# RL6845_IP_SVD register map
Vendor: Realtek
Registers are 32-bit, read-write, reset 0x0 unless marked. A register's access mark holds for its fields unless they carry their own. Offsets are from the block's base; [hi:lo] are bit positions; {n}, {i} and the like mark numbered series.

## Cap-Touch
Base 0x41012000
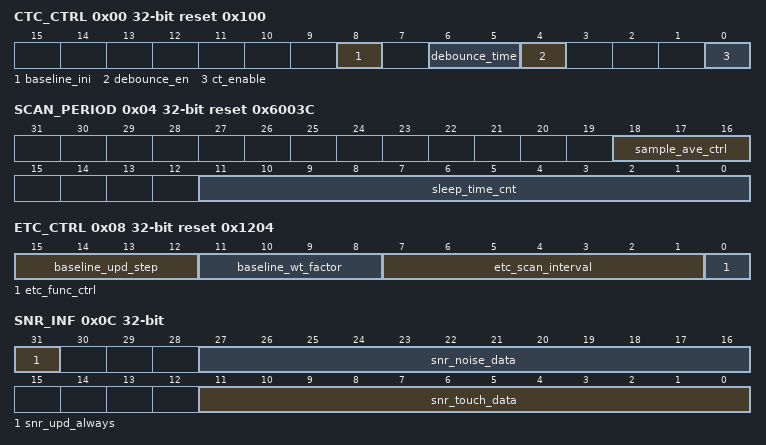
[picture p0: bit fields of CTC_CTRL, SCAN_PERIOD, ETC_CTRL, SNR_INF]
0x00 CTC_CTRL reset 0x100 — Cap-Touch Control Register
  [8] baseline_ini — 1: Baseline initial function enable, HW will clear this bit to "0" after baseline initial
  [6:5] debounce_time — 2'b00: 2 times 2'b01: 3 times 2'b10: 4 times 2'b11: 5 times
  [4] debounce_en — 0: Disable 1: Enable
  [0] ct_enable — 0: CTC disable 1: CTC enable
0x04 SCAN_PERIOD reset 0x6003C — Scan Parameters Register
  [18:16] sample_ave_ctrl — ADC sampled number for average function average number=2^(sample_ave_ctrl+2)
  [11:0] sleep_time_cnt — Code: 0~4095 (0~0xFFF), unit is 1.024kHz cycle (1/32 32.768kHz). When this register is set to 0 , HW will scan continuously and have no sleep time. Recommend value: 60~480ms
0x08 ETC_CTRL reset 0x1204 — Environment Tracking Control Register
  [15:12] baseline_upd_step — Baseline update step for all channels
  [11:8] baseline_wt_factor — Baseline update weight factor (ETC_factor_th) for all channels ETC_factor_th=2^baseline_wt_factor
  [7:1] etc_scan_interval — ETC update interval between scan period (sleep time) for all channels Interval=(etc_scan_interval+1)*scan_period
  [0] etc_func_ctrl — Environmental cap tracking calibration function 0: Disable 1: Enable
0x0C SNR_INF — Signal Noise Ratio Register
  [31] snr_upd_always — 1: Update SNR info no matter touch or not (used only in debug function)
  [27:16] snr_noise_data — Noise peak to peak signal raw data for SNR monitor
  [11:0] snr_touch_data — Raw data of touch (signal-baseline) for SNR monitor
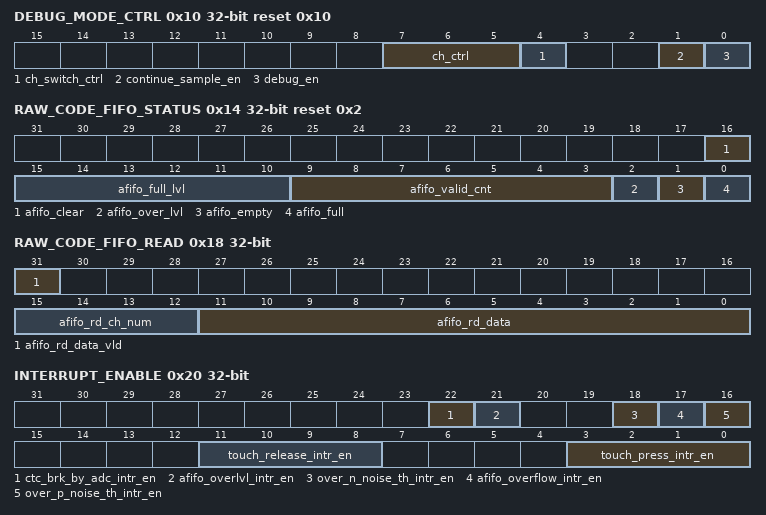
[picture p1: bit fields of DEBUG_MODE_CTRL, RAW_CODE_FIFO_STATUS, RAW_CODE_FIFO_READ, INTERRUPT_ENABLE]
0x10 DEBUG_MODE_CTRL reset 0x10 — Debug and Channel Swith Mode Register
  [7:5] ch_ctrl — Scan channel control 000: channel 0 001: channel 1 010: channel 2 011: channel 3
  [4] ch_switch_ctrl — Scan channel switch control 0: Auto switch function disable (manual switch by ch_ctrl) 1: Auto switch to next channel (channel 0 -> channel 3 -> channel 0)
  [1] continue_sample_en — Continue sample one channel mode enable, only take effect in debug mode 0: Disable 1: Enable
  [0] debug_en — Debug mode enable 0: Disable 1: Enable
0x14 RAW_CODE_FIFO_STATUS access per field reset 0x2 — FIFO Status Register
  [16] afifo_clear wo — Clear the FIFO data
  [15:10] afifo_full_lvl rw — User defines the full level for a FIFO, the valid value is from 0 to 63
  [9:3] afifo_valid_cnt ro — Raw code FIFO valid count (push unit number which can be read)
  [2] afifo_over_lvl ro — 0: Raw code FIFO not over level 1: Raw code FIFO over level
  [1] afifo_empty ro — 0: Raw code FIFO not empty 1: Raw code FIFO empty
  [0] afifo_full ro — 0: Raw code FIFO not oveflow (not full) 1: Raw code FIFO overflow (full)
0x18 RAW_CODE_FIFO_READ ro — FIFO Read Register
  [31] afifo_rd_data_vld — Read data from raw code FIFO valid
  [15:12] afifo_rd_ch_num — Read data from raw code FIFO [15:12] : channel number
  [11:0] afifo_rd_data — Read data from raw code FIFO [11:0] : data
0x20 INTERRUPT_ENABLE
  [22] ctc_brk_by_adc_intr_en — Cap-Touch breaked by ADC enable
  [21] afifo_overlvl_intr_en — Raw code FIFO over level enable
  [18] over_n_noise_th_intr_en — Negative noise threshold overflow enable
  [17] afifo_overflow_intr_en — Raw code FIFO overflow enable
  [16] over_p_noise_th_intr_en — Positive noise threshold overflow enable
  [11:8] touch_release_intr_en — Channelx single touch release enable, x is 0~3
  [3:0] touch_press_intr_en — Channelx single touch press enable, x is 0~3
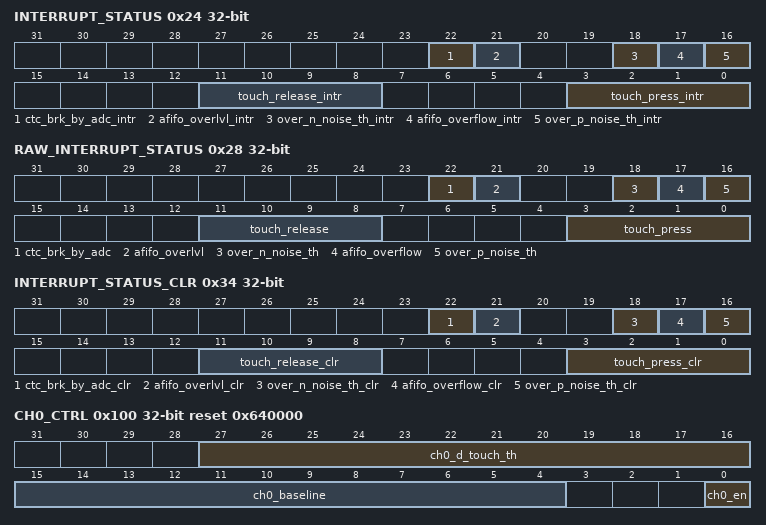
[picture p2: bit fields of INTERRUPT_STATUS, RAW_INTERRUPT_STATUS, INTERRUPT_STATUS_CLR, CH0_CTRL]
0x24 INTERRUPT_STATUS ro
  [22] ctc_brk_by_adc_intr — Cap-Touch breaked by adc interrupt
  [21] afifo_overlvl_intr — Raw code FIFO over level interrupt
  [18] over_n_noise_th_intr — Negative noise threshold overflow interrupt
  [17] afifo_overflow_intr — Raw code FIFO overflow interrupt
  [16] over_p_noise_th_intr — Positive noise threshold overflow interrupt
  [11:8] touch_release_intr — Channelx single touch release interrupt, x is 0~3
  [3:0] touch_press_intr — Channelx single touch press interrupt, x is 0~3
0x28 RAW_INTERRUPT_STATUS ro
  [22] ctc_brk_by_adc — Cap-Touch breaked by ADC raw interrupt
  [21] afifo_overlvl — Raw code FIFO over level raw interrupt
  [18] over_n_noise_th — Negative noise threshold overflow raw interrupt
  [17] afifo_overflow — Raw code FIFO overflow raw interrupt
  [16] over_p_noise_th — Positive noise threshold overflow raw interrupt
  [11:8] touch_release — Channelx single touch release raw interrupt, x is 0~3
  [3:0] touch_press — Channelx single touch press raw interrupt, x is 0~3
0x30 INTERRUPT_ALL_CLR — Interrupt All Clear Register
  [0] intr_all_clr — Write "1" to this register to clear the combined interrupts, all individual interrupts, interrupt status register and raw interrupt status register.
0x34 INTERRUPT_STATUS_CLR — Interrupt Clear Register
  [22] ctc_brk_by_adc_clr — Clear Cap-Touch breaked by adc raw interrupt and related register
  [21] afifo_overlvl_clr — Clear raw code FIFO over level raw interrupt and related register
  [18] over_n_noise_th_clr — Clear negative noise threshold overflow interrupt and related register
  [17] afifo_overflow_clr — Clear raw code FIFO overflow interrupt and related register
  [16] over_p_noise_th_clr — Clear positive noise threshold overflow interrupt and related register
  [11:8] touch_release_clr — Clear channelx single touch release interrupt and related register
  [3:0] touch_press_clr — Clear channelx single touch press interrupt and related register
0x40 DEBUG_SEL — Debug Select Register
  [2:0] dbg_sel — Debug information selection 0: dbg_clkrst 1: dbg_apbslv 2: dbg_ctrl 3: dbg_decision 4: dbg_adc_arb Others: dbg_clkrst
0x44 DEBUG_PORT ro — Debug Register
  [31:0] dbg_port — Debug port output value, depending on dbg_sel value
0x48 ECO_USE0
  [31:0] eco_use0 — For ECO use
0x4C ECO_USE1
  [31:0] eco_use1 — For ECO use
0x50 CTC_COMP_VERSION reset 0x20180123 — Version Register
  [31:0] comp_version — CTC version number
0x100 CH0_CTRL reset 0x640000 — Channel 0 Control Register
  [27:16] ch0_d_touch_th — Difference threshold data of touch judgement for channel 0. It needs to be configured during development (0x0~0xFFF) (0~4095). Init number=0x1E Recommend data=80%*(signal-baseline)
  [15:4] ch0_baseline — Digital baseline data of channel 0. Init number=0x0 It can be initialed by HW when baseline initial function enabled, and can be updated automatically by HW when ETC function enabled. It could be configured by manual tuning.
  [0] ch0_en — Cap sensor activity control of channel 0 0: Disable 1: Enable
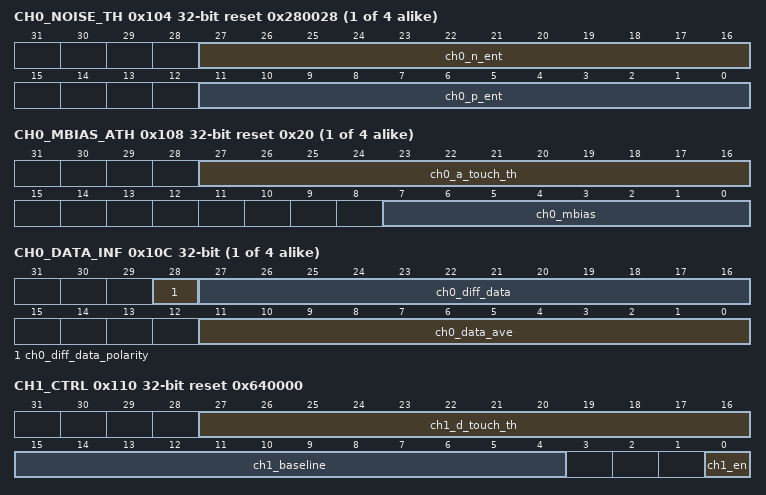
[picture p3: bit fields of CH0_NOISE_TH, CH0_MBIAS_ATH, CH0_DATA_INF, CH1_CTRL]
{0x104+0x10*i} CH{i}_NOISE_TH reset 0x280028 (i=0..3) — Channel {i} Noise Threshold Register
  [27:16] ch{i}_n_ent — The environmental negative noise threshold: the negative maximum capacitance change of raw data that is still considered an environment change.
  [11:0] ch{i}_p_ent — The environmental positive noise threshold: the positive maximum capacitance change of raw data that is still considered an environment change.
{0x108+0x10*i} CH{i}_MBIAS_ATH reset 0x20 (i=0..3) — Channel {i} Mbias
  [27:16] ch{i}_a_touch_th — Absolute threshold data of touch judgement for channel {i}. It can be updated by HW when baseline initial function or ETC function enabled, a_touch_th=baseline-d_touch_th, manual tuning when ETC disabled (0x0~0xFFF). Recommended data=80%*signal
  [7:0] ch{i}_mbias — Touch mbias current [7:0] 32u/16u/8u/4u/2u/1u/0.5u/0.25u for channel {i}
{0x10C+0x10*i} CH{i}_DATA_INF (i=0..3) — Channel {i} Dtouch Register
  [28] ch{i}_diff_data_polarity — Polarity of ch{i}_diff_data 0: ch{i}_data_ave<baseline 1: ch{i}_data_ave>=baseline
  [27:16] ch{i}_diff_data — Difference digital data of channel{i} between ch{i}_data_ave and baseline
  [11:0] ch{i}_data_ave — Average of channel {i} raw code
0x110 CH1_CTRL reset 0x640000 — Channel 0 Control Register
  [27:16] ch1_d_touch_th — Difference threshold data of touch judgement for channel 1. It needs to be configured during development (0x0~0xFFF) (0~4095). Init number=0x1E Recommend data=80%*(signal-baseline)
  [15:4] ch1_baseline — Digital baseline data of channel 1. Init number=0x0 It can be initialed by HW when baseline initial function enabled, and can be updated automatically by HW when ETC function enabled. It could be configured by manual tuning.
  [0] ch1_en — Cap sensor activity control of channel 1 0: Disable 1: Enable
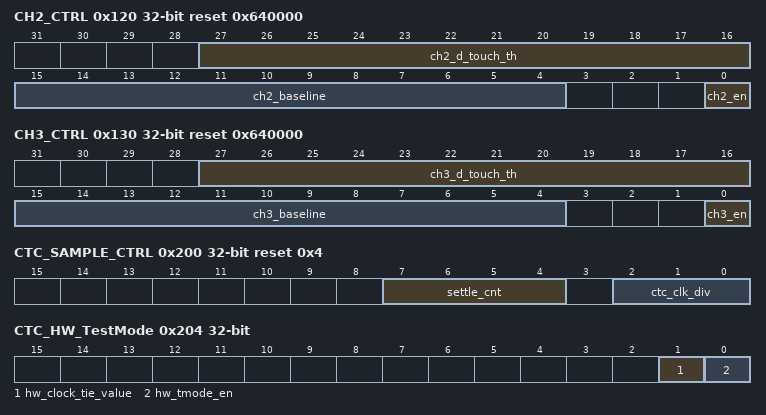
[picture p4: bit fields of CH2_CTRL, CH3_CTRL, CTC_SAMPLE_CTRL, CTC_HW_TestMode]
0x120 CH2_CTRL reset 0x640000 — Channel 2 Control Register
  [27:16] ch2_d_touch_th — Difference threshold data of touch judgement for channel 2. It needs to be configured during development (0x0~0xFFF) (0~4095). Init number=0x1E Recommend data=80%*(signal-baseline)
  [15:4] ch2_baseline — Digital baseline data of channel 2. Init number=0x0 It can be initialed by HW when baseline initial function enabled, and can be updated automatically by HW when ETC function enabled. It could be configured by manual tuning.
  [0] ch2_en — Cap sensor activity control of channel 2 0: Disable 1: Enable
0x130 CH3_CTRL reset 0x640000 — Channel 3 Control Register
  [27:16] ch3_d_touch_th — Difference threshold data of touch judgement for channel 3. It needs to be configured during development (0x0~0xFFF) (0~4095). Init number=0x1E Recommend data=80%*(signal-baseline)
  [15:4] ch3_baseline — Digital baseline data of channel 3. Init number=0x0 It can be initialed by HW when baseline initial function enabled, and can be updated automatically by HW when ETC function enabled. It could be configured by manual tuning.
  [0] ch3_en — Cap sensor activity control of channel 3 0: Disable 1: Enable
0x200 CTC_SAMPLE_CTRL reset 0x4 — Cap-Touch Sample Control Register
  [7:4] settle_cnt — Settle count for sample data from ADC to Cap-Touch, the unit is sample clock. 0 means no need to settle
  [2:0] ctc_clk_div — This field defines clock driver level of ADC module. The source clock is OSC4M. A value of 0 is for clock divided by 4. A value of 1 is for clock divided by 8. A value of 2 is for clock divided by 16. A value of 3 is for clock divided by 24. A value of 4 is for clock divided by 32. A value of 5 is for clock divided by 64. A value of 6 is for clock divided by 128.
0x204 CTC_HW_TestMode — Cap-Touch_Hardware_Test_Mode Register
  [1] hw_clock_tie_value — this value is the clock tied value in Cap-Touch hardware test mode
  [0] hw_tmode_en — 0: hardware test mode is disabled. 1: hardware test mode is enabled. The clock sent to AUX Analog from Cap-Touch is tied to fixed value, which depentS on hw_clock_tie_value (410h[1]).
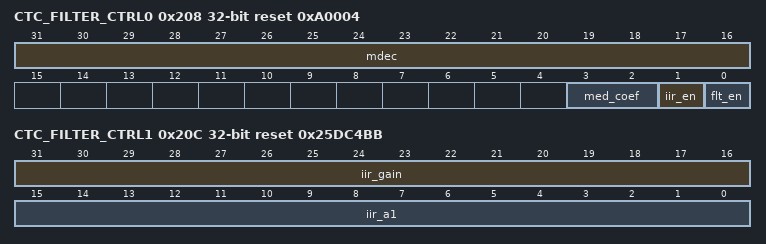
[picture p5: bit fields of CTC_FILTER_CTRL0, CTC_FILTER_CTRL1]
0x208 CTC_FILTER_CTRL0 reset 0xA0004 — Cap-Touch Filter Control0 Register
  [31:16] mdec — Decimation of sample point
  [3:2] med_coef — No use Median filter coefficient 00: disable 01: coefficient is 3 10: coefficient is 5 11: coefficient is 7
  [1] iir_en — Enable CTC IIR function
  [0] flt_en — Enable CTC filter function (global)
0x20C CTC_FILTER_CTRL1 reset 0x25DC4BB — Cap-Touch Filter Control1 Register
  [31:16] iir_gain — Gain coefficient, Q1.15
  [15:0] iir_a1 — Denominator coefficient, Q1.15
0x210 REG_CTC_DUMMY reset 0xF0 — Cap-Touch Dummy Register
  [7:0] dummy
